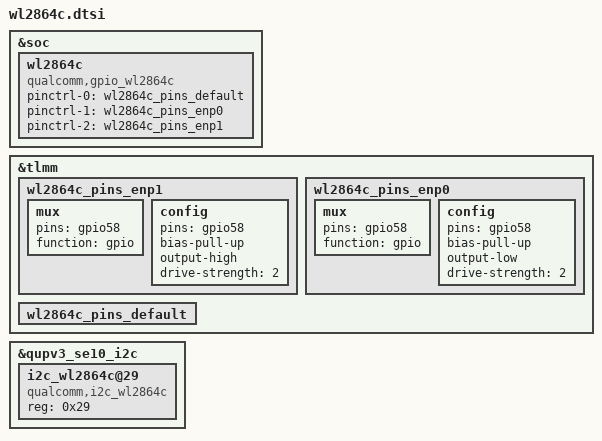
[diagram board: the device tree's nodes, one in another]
&soc {
	wl2864c:wl2864c {
		compatible = "qualcomm,gpio_wl2864c";
		pinctrl-names = "default", "wl2864c_gpio_enp0", "wl2864c_gpio_enp1";
		pinctrl-0 = <&wl2864c_pins_default>;
		pinctrl-1 = <&wl2864c_pins_enp0>;
		pinctrl-2 = <&wl2864c_pins_enp1>;
		status = "okay";
	};
};

&tlmm {
	wl2864c_pins_enp1: wl2864c_pins_enp1 {
		mux {
			pins = "gpio58";
			function = "gpio";
		};

		config {
			pins = "gpio58";
			bias-pull-up;
			output-high;
			drive-strength = <2>;
		};
	};

	wl2864c_pins_enp0: wl2864c_pins_enp0 {
		mux {
			pins = "gpio58";
			function = "gpio";
		};

		config {
			pins = "gpio58";
			bias-pull-up;
			output-low;
			drive-strength = <2>;
		};
	};

	wl2864c_pins_default: wl2864c_pins_default {
	};
};

&qupv3_se10_i2c {
	#address-cells = <1>;
	#size-cells = <0>;

	i2c_wl2864c@29{
		compatible = "qualcomm,i2c_wl2864c";
		reg = <0x29>;
		status = "okay";
	};
};

